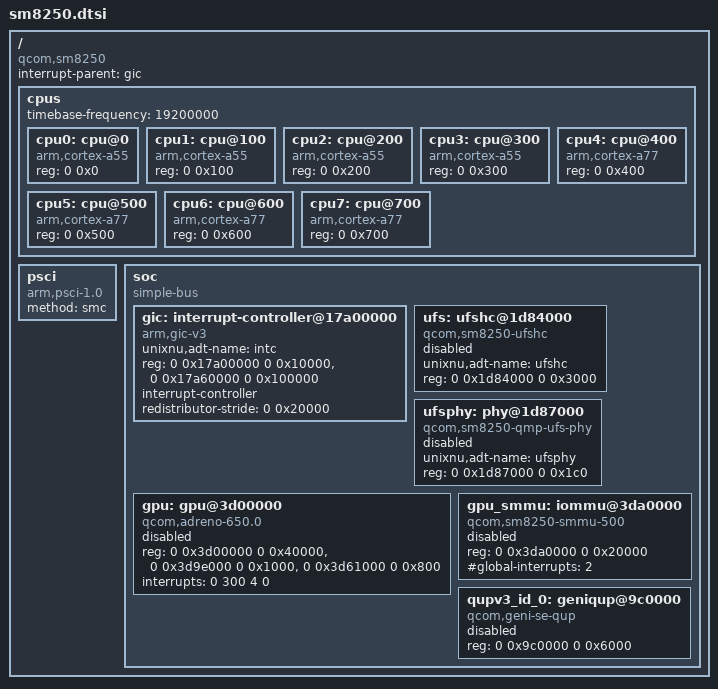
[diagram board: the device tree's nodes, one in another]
// SPDX-License-Identifier: BSD-3-Clause
// Qualcomm SM8250 (kona) shared hardware description.
//
// Values come from the SM8250 public device trees and were measured on the
// Redmi K40 (alioth). Board memory, reserved regions and peripheral policy
// belong in the board DTS.

/ {
    compatible = "qcom,sm8250";
    #address-cells = <2>;
    #size-cells = <2>;
    interrupt-parent = <&gic>;

    cpus {
        #address-cells = <2>;
        #size-cells = <0>;
        timebase-frequency = <19200000>;

        // Kryo 585 Silver, Cortex-A55.
        cpu0: cpu@0 { device_type = "cpu"; compatible = "arm,cortex-a55"; reg = <0 0x0>; };
        cpu1: cpu@100 { device_type = "cpu"; compatible = "arm,cortex-a55"; reg = <0 0x100>; };
        cpu2: cpu@200 { device_type = "cpu"; compatible = "arm,cortex-a55"; reg = <0 0x200>; };
        cpu3: cpu@300 { device_type = "cpu"; compatible = "arm,cortex-a55"; reg = <0 0x300>; };

        // Kryo 585 Gold and Gold Prime, Cortex-A77.
        cpu4: cpu@400 { device_type = "cpu"; compatible = "arm,cortex-a77"; reg = <0 0x400>; };
        cpu5: cpu@500 { device_type = "cpu"; compatible = "arm,cortex-a77"; reg = <0 0x500>; };
        cpu6: cpu@600 { device_type = "cpu"; compatible = "arm,cortex-a77"; reg = <0 0x600>; };
        cpu7: cpu@700 { device_type = "cpu"; compatible = "arm,cortex-a77"; reg = <0 0x700>; };
    };

    psci { compatible = "arm,psci-1.0"; method = "smc"; };

    soc {
        compatible = "simple-bus";
        #address-cells = <2>;
        #size-cells = <2>;
        ranges;

        // GICv3 without virtual LPIs: two 64 KiB frames per core.
        gic: interrupt-controller@17a00000 {
            compatible = "arm,gic-v3";
            unixnu,adt-name = "intc";
            reg = <0 0x17a00000 0 0x10000>, <0 0x17a60000 0 0x100000>;
            #interrupt-cells = <4>;
            #address-cells = <0>;
            interrupt-controller;
            redistributor-stride = <0 0x20000>;
        };

        // UFS host controller and PHY. The board enables them when its
        // storage component is selected.
        ufs: ufshc@1d84000 {
            compatible = "qcom,sm8250-ufshc";
            unixnu,adt-name = "ufshc";
            reg = <0 0x1d84000 0 0x3000>;
            status = "disabled";
        };

        ufsphy: phy@1d87000 {
            compatible = "qcom,sm8250-qmp-ufs-phy";
            unixnu,adt-name = "ufsphy";
            reg = <0 0x1d87000 0 0x1c0>;
            status = "disabled";
        };

        // Adreno 650 and its SMMU. The board enables them when a GPU
        // component with A650 scope is selected.
        gpu: gpu@3d00000 {
            compatible = "qcom,adreno-650.0", "qcom,adreno";
            reg = <0 0x3d00000 0 0x40000>, <0 0x3d9e000 0 0x1000>, <0 0x3d61000 0 0x800>;
            reg-names = "kgsl_3d0_reg_memory", "cx_mem", "cx_dbgc";
            interrupts = <0 300 4 0>;
            status = "disabled";
        };

        gpu_smmu: iommu@3da0000 {
            compatible = "qcom,sm8250-smmu-500", "arm,mmu-500";
            reg = <0 0x3da0000 0 0x20000>;
            #iommu-cells = <2>;
            #global-interrupts = <2>;
            status = "disabled";
        };

        // QUPv3 wrapper 0. Touch and other SPI peripherals live in its
        // serial engines; the board selects the engine it uses.
        qupv3_id_0: geniqup@9c0000 {
            compatible = "qcom,geni-se-qup";
            reg = <0 0x9c0000 0 0x6000>;
            #address-cells = <1>;
            #size-cells = <1>;
            status = "disabled";
        };
    };
};
